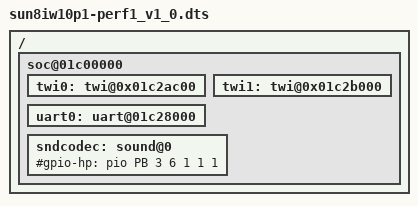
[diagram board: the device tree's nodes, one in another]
/*
 * Allwinner Technology CO., Ltd. sun50iw1p1 fpga board.
 *
 * fpga board support.
 */

/dts-v1/;

#include "sun8iw10p1.dtsi"

/{

	soc@01c00000 {
		twi0: twi@0x01c2ac00{
			status = "okay";
		};

		twi1: twi@0x01c2b000{
		  status = "okay";
		};

		uart0: uart@01c28000 {
			status = "okay";
		};

		sndcodec:sound@0{
			#gpio-hp = <&pio PB 3 6 1 1 1 >;
		};
	};
};
